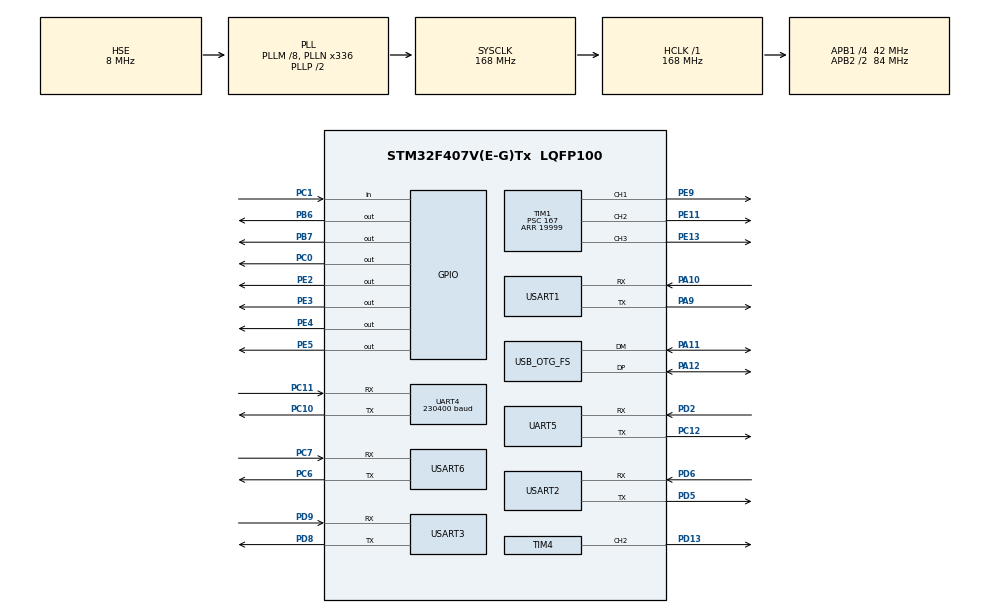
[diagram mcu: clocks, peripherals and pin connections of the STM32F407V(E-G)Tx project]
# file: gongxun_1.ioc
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Dma.Request0=UART4_RX
Dma.Request1=USART2_TX
Dma.Request10=USART3_TX
Dma.Request11=USART2_RX
Dma.Request2=TIM4_CH2
Dma.Request3=USART1_RX
Dma.Request4=USART1_TX
Dma.Request5=USART6_RX
Dma.Request6=USART6_TX
Dma.Request7=UART5_RX
Dma.Request8=UART5_TX
Dma.Request9=USART3_RX
Dma.TIM4_CH2.2.Direction=DMA_MEMORY_TO_PERIPH
Dma.TIM4_CH2.2.FIFOMode=DMA_FIFOMODE_DISABLE
Dma.TIM4_CH2.2.Instance=DMA1_Stream3
Dma.TIM4_CH2.2.MemDataAlignment=DMA_MDATAALIGN_HALFWORD
Dma.TIM4_CH2.2.MemInc=DMA_MINC_ENABLE
Dma.TIM4_CH2.2.Mode=DMA_NORMAL
Dma.TIM4_CH2.2.PeriphDataAlignment=DMA_PDATAALIGN_HALFWORD
Dma.TIM4_CH2.2.PeriphInc=DMA_PINC_DISABLE
Dma.TIM4_CH2.2.Priority=DMA_PRIORITY_LOW
Dma.UART4_RX.0.Direction=DMA_PERIPH_TO_MEMORY
Dma.UART4_RX.0.FIFOMode=DMA_FIFOMODE_DISABLE
Dma.UART4_RX.0.Instance=DMA1_Stream2
Dma.UART4_RX.0.MemDataAlignment=DMA_MDATAALIGN_BYTE
Dma.UART4_RX.0.MemInc=DMA_MINC_ENABLE
Dma.UART4_RX.0.Mode=DMA_CIRCULAR
Dma.UART4_RX.0.PeriphDataAlignment=DMA_PDATAALIGN_BYTE
Dma.UART4_RX.0.PeriphInc=DMA_PINC_DISABLE
Dma.UART4_RX.0.Priority=DMA_PRIORITY_MEDIUM
Dma.UART5_RX.7.Direction=DMA_PERIPH_TO_MEMORY
Dma.UART5_RX.7.FIFOMode=DMA_FIFOMODE_DISABLE
Dma.UART5_RX.7.Instance=DMA1_Stream0
Dma.UART5_RX.7.MemDataAlignment=DMA_MDATAALIGN_BYTE
Dma.UART5_RX.7.MemInc=DMA_MINC_ENABLE
Dma.UART5_RX.7.Mode=DMA_NORMAL
Dma.UART5_RX.7.PeriphDataAlignment=DMA_PDATAALIGN_BYTE
Dma.UART5_RX.7.PeriphInc=DMA_PINC_DISABLE
Dma.UART5_RX.7.Priority=DMA_PRIORITY_LOW
Dma.UART5_TX.8.Direction=DMA_MEMORY_TO_PERIPH
Dma.UART5_TX.8.FIFOMode=DMA_FIFOMODE_DISABLE
Dma.UART5_TX.8.Instance=DMA1_Stream7
Dma.UART5_TX.8.MemDataAlignment=DMA_MDATAALIGN_BYTE
Dma.UART5_TX.8.MemInc=DMA_MINC_ENABLE
Dma.UART5_TX.8.Mode=DMA_NORMAL
Dma.UART5_TX.8.PeriphDataAlignment=DMA_PDATAALIGN_BYTE
Dma.UART5_TX.8.PeriphInc=DMA_PINC_DISABLE
Dma.UART5_TX.8.Priority=DMA_PRIORITY_LOW
Dma.USART1_RX.3.Direction=DMA_PERIPH_TO_MEMORY
Dma.USART1_RX.3.FIFOMode=DMA_FIFOMODE_DISABLE
Dma.USART1_RX.3.Instance=DMA2_Stream2
Dma.USART1_RX.3.MemDataAlignment=DMA_MDATAALIGN_BYTE
Dma.USART1_RX.3.MemInc=DMA_MINC_ENABLE
Dma.USART1_RX.3.Mode=DMA_CIRCULAR
Dma.USART1_RX.3.PeriphDataAlignment=DMA_PDATAALIGN_BYTE
Dma.USART1_RX.3.PeriphInc=DMA_PINC_DISABLE
Dma.USART1_RX.3.Priority=DMA_PRIORITY_LOW
Dma.USART1_TX.4.Direction=DMA_MEMORY_TO_PERIPH
Dma.USART1_TX.4.FIFOMode=DMA_FIFOMODE_DISABLE
Dma.USART1_TX.4.Instance=DMA2_Stream7
Dma.USART1_TX.4.MemDataAlignment=DMA_MDATAALIGN_BYTE
Dma.USART1_TX.4.MemInc=DMA_MINC_ENABLE
Dma.USART1_TX.4.Mode=DMA_NORMAL
Dma.USART1_TX.4.PeriphDataAlignment=DMA_PDATAALIGN_BYTE
Dma.USART1_TX.4.PeriphInc=DMA_PINC_DISABLE
Dma.USART1_TX.4.Priority=DMA_PRIORITY_LOW
Dma.USART2_RX.11.Direction=DMA_PERIPH_TO_MEMORY
Dma.USART2_RX.11.FIFOMode=DMA_FIFOMODE_DISABLE
Dma.USART2_RX.11.Instance=DMA1_Stream5
Dma.USART2_RX.11.MemDataAlignment=DMA_MDATAALIGN_BYTE
Dma.USART2_RX.11.MemInc=DMA_MINC_ENABLE
Dma.USART2_RX.11.Mode=DMA_CIRCULAR
Dma.USART2_RX.11.PeriphDataAlignment=DMA_PDATAALIGN_BYTE
Dma.USART2_RX.11.PeriphInc=DMA_PINC_DISABLE
Dma.USART2_RX.11.Priority=DMA_PRIORITY_MEDIUM
Dma.USART2_TX.1.Direction=DMA_MEMORY_TO_PERIPH
Dma.USART2_TX.1.FIFOMode=DMA_FIFOMODE_DISABLE
Dma.USART2_TX.1.Instance=DMA1_Stream6
Dma.USART2_TX.1.MemDataAlignment=DMA_MDATAALIGN_BYTE
Dma.USART2_TX.1.MemInc=DMA_MINC_ENABLE
Dma.USART2_TX.1.Mode=DMA_NORMAL
Dma.USART2_TX.1.PeriphDataAlignment=DMA_PDATAALIGN_BYTE
Dma.USART2_TX.1.PeriphInc=DMA_PINC_DISABLE
Dma.USART2_TX.1.Priority=DMA_PRIORITY_MEDIUM
Dma.USART3_RX.9.Direction=DMA_PERIPH_TO_MEMORY
Dma.USART3_RX.9.FIFOMode=DMA_FIFOMODE_DISABLE
Dma.USART3_RX.9.Instance=DMA1_Stream1
Dma.USART3_RX.9.MemDataAlignment=DMA_MDATAALIGN_BYTE
Dma.USART3_RX.9.MemInc=DMA_MINC_ENABLE
Dma.USART3_RX.9.Mode=DMA_CIRCULAR
Dma.USART3_RX.9.PeriphDataAlignment=DMA_PDATAALIGN_BYTE
Dma.USART3_RX.9.PeriphInc=DMA_PINC_DISABLE
Dma.USART3_RX.9.Priority=DMA_PRIORITY_LOW
Dma.USART3_TX.10.Direction=DMA_MEMORY_TO_PERIPH
Dma.USART3_TX.10.FIFOMode=DMA_FIFOMODE_DISABLE
Dma.USART3_TX.10.Instance=DMA1_Stream4
Dma.USART3_TX.10.MemDataAlignment=DMA_MDATAALIGN_BYTE
Dma.USART3_TX.10.MemInc=DMA_MINC_ENABLE
Dma.USART3_TX.10.Mode=DMA_NORMAL
Dma.USART3_TX.10.PeriphDataAlignment=DMA_PDATAALIGN_BYTE
Dma.USART3_TX.10.PeriphInc=DMA_PINC_DISABLE
Dma.USART3_TX.10.Priority=DMA_PRIORITY_LOW
Dma.USART6_RX.5.Direction=DMA_PERIPH_TO_MEMORY
Dma.USART6_RX.5.FIFOMode=DMA_FIFOMODE_DISABLE
Dma.USART6_RX.5.Instance=DMA2_Stream1
Dma.USART6_RX.5.MemDataAlignment=DMA_MDATAALIGN_BYTE
Dma.USART6_RX.5.MemInc=DMA_MINC_ENABLE
Dma.USART6_RX.5.Mode=DMA_NORMAL
Dma.USART6_RX.5.PeriphDataAlignment=DMA_PDATAALIGN_BYTE
Dma.USART6_RX.5.PeriphInc=DMA_PINC_DISABLE
Dma.USART6_RX.5.Priority=DMA_PRIORITY_LOW
Dma.USART6_TX.6.Direction=DMA_MEMORY_TO_PERIPH
Dma.USART6_TX.6.FIFOMode=DMA_FIFOMODE_DISABLE
Dma.USART6_TX.6.Instance=DMA2_Stream6
Dma.USART6_TX.6.MemDataAlignment=DMA_MDATAALIGN_BYTE
Dma.USART6_TX.6.MemInc=DMA_MINC_ENABLE
Dma.USART6_TX.6.Mode=DMA_NORMAL
Dma.USART6_TX.6.PeriphDataAlignment=DMA_PDATAALIGN_BYTE
Dma.USART6_TX.6.PeriphInc=DMA_PINC_DISABLE
Dma.USART6_TX.6.Priority=DMA_PRIORITY_LOW
Mcu.Family=STM32F4
Mcu.Name=STM32F407V(E-G)Tx
Mcu.Package=LQFP100
NVIC.DMA1_Stream0_IRQn=true\:0\:0\:false\:false\:true\:false\:true\:true
NVIC.DMA1_Stream1_IRQn=true\:0\:0\:false\:false\:true\:false\:true\:true
NVIC.DMA1_Stream2_IRQn=true\:0\:0\:false\:false\:true\:false\:true\:true
NVIC.DMA1_Stream3_IRQn=true\:0\:0\:false\:false\:true\:false\:true\:true
NVIC.DMA1_Stream4_IRQn=true\:0\:0\:false\:false\:true\:false\:true\:true
NVIC.DMA1_Stream5_IRQn=true\:0\:0\:false\:false\:true\:false\:true\:true
NVIC.DMA1_Stream6_IRQn=true\:0\:0\:false\:false\:true\:false\:true\:true
NVIC.DMA1_Stream7_IRQn=true\:0\:0\:false\:false\:true\:false\:true\:true
NVIC.DMA2_Stream1_IRQn=true\:0\:0\:false\:false\:true\:false\:true\:true
NVIC.DMA2_Stream2_IRQn=true\:0\:0\:false\:false\:true\:false\:true\:true
NVIC.DMA2_Stream6_IRQn=true\:0\:0\:false\:false\:true\:false\:true\:true
NVIC.DMA2_Stream7_IRQn=true\:0\:0\:false\:false\:true\:false\:true\:true
NVIC.OTG_FS_IRQn=true\:0\:0\:false\:false\:true\:false\:true\:true
NVIC.PriorityGroup=NVIC_PRIORITYGROUP_4
NVIC.TIM2_IRQn=true\:0\:0\:false\:false\:true\:true\:true\:true
NVIC.TIM4_IRQn=true\:0\:0\:false\:false\:true\:true\:true\:true
NVIC.TIM6_DAC_IRQn=true\:0\:0\:false\:false\:true\:true\:true\:true
NVIC.TIM7_IRQn=true\:0\:0\:false\:false\:true\:true\:true\:true
NVIC.UART4_IRQn=true\:0\:0\:false\:false\:true\:true\:true\:true
NVIC.UART5_IRQn=true\:0\:0\:false\:false\:true\:true\:true\:true
NVIC.USART1_IRQn=true\:0\:0\:false\:false\:true\:true\:true\:true
NVIC.USART2_IRQn=true\:0\:0\:false\:false\:true\:true\:true\:true
NVIC.USART3_IRQn=true\:0\:0\:false\:false\:true\:true\:true\:true
NVIC.USART6_IRQn=true\:0\:0\:false\:false\:true\:true\:true\:true
PA10.GPIO_PuPd=GPIO_PULLUP
PA10.Mode=Asynchronous
PA10.Signal=USART1_RX
PA11.Mode=Device_Only
PA11.Signal=USB_OTG_FS_DM
PA12.Mode=Device_Only
PA12.Signal=USB_OTG_FS_DP
PA13.Mode=Serial_Wire
PA13.Signal=SYS_JTMS-SWDIO
PA14.Mode=Serial_Wire
PA14.Signal=SYS_JTCK-SWCLK
PA9.Mode=Asynchronous
PA9.Signal=USART1_TX
PB6.GPIO_PuPd=GPIO_PULLUP
PB6.PinState=GPIO_PIN_SET
PB6.Signal=GPIO_Output
PB7.GPIO_PuPd=GPIO_PULLUP
PB7.PinState=GPIO_PIN_SET
PB7.Signal=GPIO_Output
PC0.GPIO_PuPd=GPIO_NOPULL
PC0.PinState=GPIO_PIN_SET
PC0.Signal=GPIO_Output
PC1.GPIO_PuPd=GPIO_PULLUP
PC1.Signal=GPIO_Input
PC10.Mode=Asynchronous
PC10.Signal=UART4_TX
PC11.Mode=Asynchronous
PC11.Signal=UART4_RX
PC12.Mode=Asynchronous
PC12.Signal=UART5_TX
PC6.Mode=Asynchronous
PC6.Signal=USART6_TX
PC7.Mode=Asynchronous
PC7.Signal=USART6_RX
PD13.Signal=S_TIM4_CH2
PD2.Mode=Asynchronous
PD2.Signal=UART5_RX
PD5.Mode=Asynchronous
PD5.Signal=USART2_TX
PD6.Mode=Asynchronous
PD6.Signal=USART2_RX
PD8.Mode=Asynchronous
PD8.Signal=USART3_TX
PD9.Mode=Asynchronous
PD9.Signal=USART3_RX
PE11.Signal=S_TIM1_CH2
PE13.Signal=S_TIM1_CH3
PE2.GPIO_PuPd=GPIO_PULLUP
PE2.Signal=GPIO_Output
PE3.GPIO_PuPd=GPIO_PULLUP
PE3.PinState=GPIO_PIN_SET
PE3.Signal=GPIO_Output
PE4.GPIO_PuPd=GPIO_PULLUP
PE4.PinState=GPIO_PIN_SET
PE4.Signal=GPIO_Output
PE5.GPIO_PuPd=GPIO_PULLUP
PE5.PinState=GPIO_PIN_SET
PE5.Signal=GPIO_Output
PE9.Signal=S_TIM1_CH1
PH0-OSC_IN.Mode=HSE-External-Oscillator
PH0-OSC_IN.Signal=RCC_OSC_IN
PH1-OSC_OUT.Mode=HSE-External-Oscillator
PH1-OSC_OUT.Signal=RCC_OSC_OUT
ProjectManager.HeapSize=0x200
ProjectManager.StackSize=0x400
ProjectManager.TargetToolchain=CMake
RCC.48MHZClocksFreq_Value=48000000
RCC.AHBFreq_Value=168000000
RCC.APB1CLKDivider=RCC_HCLK_DIV4
RCC.APB1Freq_Value=42000000
RCC.APB1TimFreq_Value=84000000
RCC.APB2CLKDivider=RCC_HCLK_DIV2
RCC.APB2Freq_Value=84000000
RCC.APB2TimFreq_Value=168000000
RCC.CortexFreq_Value=168000000
RCC.HCLKFreq_Value=168000000
RCC.HSE_VALUE=8000000
RCC.HSI_VALUE=16000000
RCC.LSE_VALUE=32768
RCC.PLLM=8
RCC.PLLN=336
RCC.PLLQ=7
RCC.SYSCLKFreq_VALUE=168000000
RCC.SYSCLKSource=RCC_SYSCLKSOURCE_PLLCLK
RCC.VCOOutputFreq_Value=336000000
SH.S_TIM1_CH1.0=TIM1_CH1,PWM Generation1 CH1
SH.S_TIM1_CH2.0=TIM1_CH2,PWM Generation2 CH2
SH.S_TIM1_CH3.0=TIM1_CH3,PWM Generation3 CH3
SH.S_TIM4_CH2.0=TIM4_CH2,PWM Generation2 CH2
TIM1.AutoReloadPreload=TIM_AUTORELOAD_PRELOAD_ENABLE
TIM1.Channel-PWM\ Generation1\ CH1=TIM_CHANNEL_1
TIM1.Channel-PWM\ Generation2\ CH2=TIM_CHANNEL_2
TIM1.Channel-PWM\ Generation3\ CH3=TIM_CHANNEL_3
TIM1.Period=19999
TIM1.Prescaler=167
TIM2.AutoReloadPreload=TIM_AUTORELOAD_PRELOAD_ENABLE
TIM2.Period=9999
TIM2.Prescaler=83
TIM4.AutoReloadPreload=TIM_AUTORELOAD_PRELOAD_ENABLE
TIM4.Channel-PWM\ Generation2\ CH2=TIM_CHANNEL_2
TIM4.Period=104
TIM6.AutoReloadPreload=TIM_AUTORELOAD_PRELOAD_ENABLE
TIM6.Period=1000 - 1
TIM6.Prescaler=84 - 1
TIM7.AutoReloadPreload=TIM_AUTORELOAD_PRELOAD_ENABLE
TIM7.Period=5000 - 1
TIM7.Prescaler=84 - 1 
UART4.BaudRate=230400
UART4.VirtualMode=Asynchronous
UART5.VirtualMode=Asynchronous
USART1.VirtualMode=VM_ASYNC
USART2.VirtualMode=VM_ASYNC
USART3.VirtualMode=VM_ASYNC
USART6.VirtualMode=VM_ASYNC
USB_DEVICE.CLASS_NAME_FS=CDC
USB_DEVICE.VirtualMode-CDC_FS=Cdc
USB_DEVICE.VirtualModeFS=Cdc_FS
USB_OTG_FS.VirtualMode=Device_Only
VP_TIM1_VS_ClockSourceINT.Mode=Internal
VP_TIM2_VS_ClockSourceINT.Mode=Internal
VP_TIM4_VS_ClockSourceINT.Mode=Internal
VP_TIM6_VS_ClockSourceINT.Mode=Enable_Timer
VP_TIM7_VS_ClockSourceINT.Mode=Enable_Timer
VP_USB_DEVICE_VS_USB_DEVICE_CDC_FS.Mode=CDC_FS
board=custom

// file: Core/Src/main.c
/* USER CODE BEGIN Header */
/**
  ******************************************************************************
  * @file           : main.c
  * @brief          : Main program body
  ******************************************************************************
  * @attention
  *
  * Copyright (c) 2026 STMicroelectronics.
  * All rights reserved.
  *
  * This software is licensed under terms that can be found in the LICENSE file
  * in the root directory of this software component.
  * If no LICENSE file comes with this software, it is provided AS-IS.
  *
  ******************************************************************************
  */
/* USER CODE END Header */
#include "main.h"
#include "dma.h"
#include "tim.h"
#include "usart.h"
#include "usb_device.h"
#include "gpio.h"

/* USER CODE BEGIN Includes */
#include "headfile.h"

/* USER CODE END Includes */

void SystemClock_Config(void);

/* USER CODE BEGIN 0 */
uint8_t perfect_ok = 0;  // 完赛标志
/* USER CODE END 0 */

int main(void)
{

  /* MCU Configuration--------------------------------------------------------*/

  /* Reset of all peripherals, Initializes the Flash interface and the Systick. */
  HAL_Init();

  /* Configure the system clock */
  SystemClock_Config();

  /* Initialize all configured peripherals */
  MX_GPIO_Init();
  MX_DMA_Init();
  MX_USB_DEVICE_Init();
  MX_UART4_Init();
  MX_USART1_UART_Init();
  MX_TIM6_Init();
  MX_TIM7_Init();
  MX_USART3_UART_Init();
  MX_USART6_UART_Init();
  MX_TIM1_Init();
  MX_UART5_Init();
  MX_USART2_UART_Init();
  MX_TIM2_Init();
  MX_TIM4_Init();
  /* USER CODE BEGIN 2 */

  // 整车初始化含等待和机构准备，只在主循环上下文执行；调用关系见根目录 docs/architecture.md。
  // 系统整体初始化
  system_init();
  perfect_ok = 0;
  // uint32_t tim = HAL_GetTick();

  // maix 任务一测试
  // maix_b2_test();

  // openmv测试
  // openmv_test();

  /* USER CODE END 2 */

  /* Infinite loop */
  /* USER CODE BEGIN WHILE */

  while (1)
  {
    // 主循环消费摄像头缓存、维护视觉超时并发送挂起命令；比赛控制由 TIM2 的 10ms 回调推进。
    // mv_task 内含扫码服务等待，因此这里不是固定周期，也不能保证所有路径完全无阻塞。
    cam_task();               // 解析摄像头数据
    mv_task();                // OpenMV扫码处理任务

    if (perfect_ok == 1) {
      HAL_Delay(10);
      hmi_ChangePage("end");
      perfect_ok = 0;
      HAL_Delay(10);
    }

    // if (HAL_GetTick() - tim >= 700) {
    //   tim = HAL_GetTick();
    //   printf("偏航角：%.2f \n",my_yaw);
    // }

    // 当前正式入口未周期调用 chassis_odom_tick/map_obstacle_pose_task/map_nav_task。
    // 下方雷达解析也保持关闭；模块已编译不等于已接入比赛流程，本次注释整理不改变这些开关。
    // hmi_get_car_state_task(); // 非阻塞式发送小车当前状态至串口屏任务
    // lidar_process();          // 雷达DMA数据解析

    /* USER CODE END WHILE */

  }
}

void SystemClock_Config(void)
{
  RCC_OscInitTypeDef RCC_OscInitStruct = {0};
  RCC_ClkInitTypeDef RCC_ClkInitStruct = {0};

  /** Configure the main internal regulator output voltage
  */
  __HAL_RCC_PWR_CLK_ENABLE();
  __HAL_PWR_VOLTAGESCALING_CONFIG(PWR_REGULATOR_VOLTAGE_SCALE1);

  /** Initializes the RCC Oscillators according to the specified parameters
  * in the RCC_OscInitTypeDef structure.
  */
  RCC_OscInitStruct.OscillatorType = RCC_OSCILLATORTYPE_HSE;
  RCC_OscInitStruct.HSEState = RCC_HSE_ON;
  RCC_OscInitStruct.PLL.PLLState = RCC_PLL_ON;
  RCC_OscInitStruct.PLL.PLLSource = RCC_PLLSOURCE_HSE;
  RCC_OscInitStruct.PLL.PLLM = 8;
  RCC_OscInitStruct.PLL.PLLN = 336;
  RCC_OscInitStruct.PLL.PLLP = RCC_PLLP_DIV2;
  RCC_OscInitStruct.PLL.PLLQ = 7;
  if (HAL_RCC_OscConfig(&RCC_OscInitStruct) != HAL_OK)
  {
    Error_Handler();
  }

  /** Initializes the CPU, AHB and APB buses clocks
  */
  RCC_ClkInitStruct.ClockType = RCC_CLOCKTYPE_HCLK|RCC_CLOCKTYPE_SYSCLK
                              |RCC_CLOCKTYPE_PCLK1|RCC_CLOCKTYPE_PCLK2;
  RCC_ClkInitStruct.SYSCLKSource = RCC_SYSCLKSOURCE_PLLCLK;
  RCC_ClkInitStruct.AHBCLKDivider = RCC_SYSCLK_DIV1;
  RCC_ClkInitStruct.APB1CLKDivider = RCC_HCLK_DIV4;
  RCC_ClkInitStruct.APB2CLKDivider = RCC_HCLK_DIV2;

  if (HAL_RCC_ClockConfig(&RCC_ClkInitStruct, FLASH_LATENCY_5) != HAL_OK)
  {
    Error_Handler();
  }
}

/* USER CODE BEGIN 4 */

// 重定向 printf 到 串口6  可以无线串口 调参
// int _write(int file,char *ptr,int len)
// {
//   HAL_UART_Transmit(&huart6,(uint8_t *)ptr,len,100);
//
//   return len;
// }

// // 重定向 printf 到 虚拟串口 CDC
// extern USBD_HandleTypeDef hUsbDeviceFS;
//
// int _write(int file, char *ptr, int len)
// {
//   (void)file;
//
//   if (hUsbDeviceFS.dev_state != USBD_STATE_CONFIGURED) {
//     return len;
//   }
//
//   uint32_t start = HAL_GetTick();
//
//   while (CDC_Transmit_FS((uint8_t *)ptr, len) != USBD_OK) {
//     if (HAL_GetTick() - start > 20) {
//       break;
//     }
//   }
//
//   return len;
// }

/* USER CODE END 4 */

void Error_Handler(void)
{
  __disable_irq();
  while (1)
  {
  }
}
